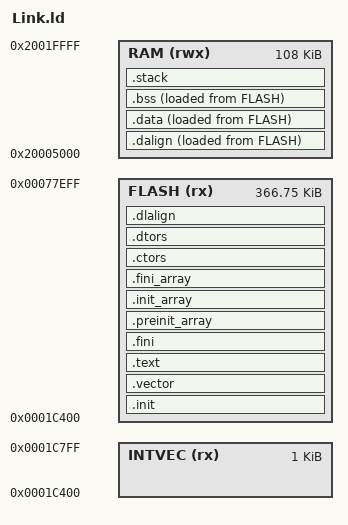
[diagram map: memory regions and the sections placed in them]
/*======================================================================
**文件名称：STM32L431RCTX_FLASH.ld（链接文件）
**制作单位：SD-Arm(sumcu.suda.edu.cn)
**更新记录：20181201-20200629
**======================================================================*/


/*（1）【变动】相关常数定义*/
MCU_SECTORSIZE =256; 
MCU_FLASH_ADDR_START = 0x00000000;    /*CH32V307CVT6的FLASH起始地址*/
GEC_USER_SECTOR_START  =452;          /*USER程序开始扇区号*/
GEC_USER_SECTOR_END =1919;             /*USER程序结束扇区号 */
GEC_USER_RAM_START =0x20005000;       /*USER RAM区域起始地址  */
GEC_USER_RAM_END  =0x20020000;        /*USER RAM区域结束地址*/
 _eusrstack =  0x20020000;	              /*BIOS RAM区域结束地址（用于启动文件）*/



ENTRY( _start ) 

__stack_size = 2048;

PROVIDE( _stack_size = __stack_size );

/*
MEMORY
{
	FLASH (rx) : ORIGIN = 0x00000000, LENGTH = 256K
	RAM (xrw) : ORIGIN = 0x20000000, LENGTH = 128K
}
*/

/*（2）【固定】MEMORY段定义*/
MEMORY
{
	/*中断向量表*/

    INTVEC(rx) : ORIGIN =MCU_SECTORSIZE * (GEC_USER_SECTOR_START) + MCU_FLASH_ADDR_START, 
	              LENGTH = MCU_SECTORSIZE * 4

	/*Flash代码区*/                   
    FLASH (rx) : ORIGIN = MCU_FLASH_ADDR_START + MCU_SECTORSIZE * (GEC_USER_SECTOR_START), 
                  LENGTH = MCU_SECTORSIZE * (GEC_USER_SECTOR_END - GEC_USER_SECTOR_START )
    
    /*User程序RAM区*/
    RAM  (rwx) : ORIGIN = GEC_USER_RAM_START, 
                  LENGTH = GEC_USER_RAM_END - GEC_USER_RAM_START
}



SECTIONS
{
/* （3.1）【固定】中断向量表 */
/*
 .isr_vector :
  {
    . = ALIGN(4);
    KEEP(*(.isr_vector)) 
    . = ALIGN(4);
  } >INTVEC AT>INTVEC
*/
/*------------------------原始----------------------------*/

	.init :
	{
		_sinit = .;
		. = ALIGN(4);
		KEEP(*(SORT_NONE(.init)))
		. = ALIGN(4);
		_einit = .;
	} >FLASH AT>FLASH
	

  .vector :
  {
      *(.vector);
	  . = ALIGN(64);
  } >FLASH AT>FLASH

	.text :
	{
		. = ALIGN(4);
		*(.text)
		*(.text.*)
		*(.rodata)
		*(.rodata*)
		*(.glue_7)
		*(.glue_7t)
		*(.gnu.linkonce.t.*)
		. = ALIGN(4);
	} >FLASH AT>FLASH 

	.fini :
	{
		KEEP(*(SORT_NONE(.fini)))
		. = ALIGN(4);
	} >FLASH AT>FLASH

	PROVIDE( _etext = . );
	PROVIDE( _eitcm = . );	

	.preinit_array  :
	{
	  PROVIDE_HIDDEN (__preinit_array_start = .);
	  KEEP (*(.preinit_array))
	  PROVIDE_HIDDEN (__preinit_array_end = .);
	} >FLASH AT>FLASH 
	
	.init_array     :
	{
	  PROVIDE_HIDDEN (__init_array_start = .);
	  KEEP (*(SORT_BY_INIT_PRIORITY(.init_array.*) SORT_BY_INIT_PRIORITY(.ctors.*)))
	  KEEP (*(.init_array EXCLUDE_FILE (*crtbegin.o *crtbegin?.o *crtend.o *crtend?.o ) .ctors))
	  PROVIDE_HIDDEN (__init_array_end = .);
	} >FLASH AT>FLASH 
	
	.fini_array     :
	{
	  PROVIDE_HIDDEN (__fini_array_start = .);
	  KEEP (*(SORT_BY_INIT_PRIORITY(.fini_array.*) SORT_BY_INIT_PRIORITY(.dtors.*)))
	  KEEP (*(.fini_array EXCLUDE_FILE (*crtbegin.o *crtbegin?.o *crtend.o *crtend?.o ) .dtors))
	  PROVIDE_HIDDEN (__fini_array_end = .);
	} >FLASH AT>FLASH 
	
	.ctors          :
	{
	  /* gcc uses crtbegin.o to find the start of
	     the constructors, so we make sure it is
	     first.  Because this is a wildcard, it
	     doesn't matter if the user does not
	     actually link against crtbegin.o; the
	     linker won't look for a file to match a
	     wildcard.  The wildcard also means that it
	     doesn't matter which directory crtbegin.o
	     is in.  */
	  KEEP (*crtbegin.o(.ctors))
	  KEEP (*crtbegin?.o(.ctors))
	  /* We don't want to include the .ctor section from
	     the crtend.o file until after the sorted ctors.
	     The .ctor section from the crtend file contains the
	     end of ctors marker and it must be last */
	  KEEP (*(EXCLUDE_FILE (*crtend.o *crtend?.o ) .ctors))
	  KEEP (*(SORT(.ctors.*)))
	  KEEP (*(.ctors))
	} >FLASH AT>FLASH 
	
	.dtors          :
	{
	  KEEP (*crtbegin.o(.dtors))
	  KEEP (*crtbegin?.o(.dtors))
	  KEEP (*(EXCLUDE_FILE (*crtend.o *crtend?.o ) .dtors))
	  KEEP (*(SORT(.dtors.*)))
	  KEEP (*(.dtors))
	} >FLASH AT>FLASH 

	.dalign :
	{
		. = ALIGN(4);
		PROVIDE(_data_vma = .);
	} >RAM AT>FLASH	

	.dlalign :
	{
		. = ALIGN(4); 
		PROVIDE(_data_lma = .);
	} >FLASH AT>FLASH

	.data :
	{
    	*(.gnu.linkonce.r.*)
    	*(.data .data.*)
    	*(.gnu.linkonce.d.*)
		. = ALIGN(8);
    	PROVIDE( __global_pointer$ = . + 0x800 );
    	*(.sdata .sdata.*)
		*(.sdata2.*)
    	*(.gnu.linkonce.s.*)
    	. = ALIGN(8);
    	*(.srodata.cst16)
    	*(.srodata.cst8)
    	*(.srodata.cst4)
    	*(.srodata.cst2)
    	*(.srodata .srodata.*)
    	. = ALIGN(4);
		PROVIDE( _edata = .);
	} >RAM AT>FLASH

	.bss :
	{
		. = ALIGN(4);
		PROVIDE( _sbss = .);
  	    *(.sbss*)
        *(.gnu.linkonce.sb.*)
		*(.bss*)
     	*(.gnu.linkonce.b.*)		
		*(COMMON*)
		. = ALIGN(4);
		PROVIDE( _ebss = .);
	} >RAM AT>FLASH

	PROVIDE( _end = _ebss);
	PROVIDE( end = . );

    .stack ORIGIN(RAM) + LENGTH(RAM) - __stack_size :
    {
        . = ALIGN(4);
        PROVIDE(_susrstack = . );
        . = . + __stack_size;
        PROVIDE( _eusrstack = .);
    } >RAM 

}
